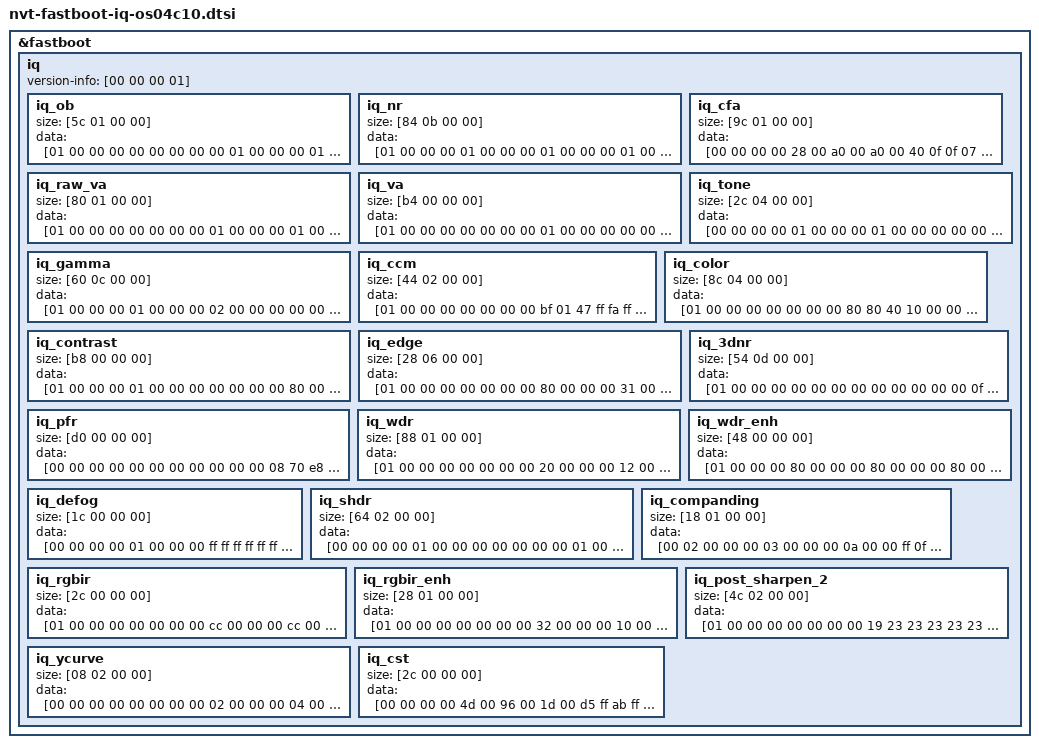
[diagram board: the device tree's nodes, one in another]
/*
 * Novatek Ltd. NVT98567 ISP part of dts
 */

&fastboot {
	iq {
		version-info = [00 00 00 01];
		iq_ob {
			size = [5c 01 00 00];
			data = [01 00 00 00 00 00 00 00 00 01 00 00 00 01 00 00 00 01 00 00 00 01 00 00 00 01 00 00 00 01 00 00 00 01 00 00 00 01 00 00 00 01 00 00 00 01 00 00 00 01 00 00 00 01 00 00 00 01 00 00 00 01 00 00 00 01 00 00 00 01 00 00 00 01 00 00 00 01 00 00 00 01 00 00 00 01 00 00 00 01 00 00 00 01 00 00 00 01 00 00 00 01 00 00 00 01 00 00 00 01 00 00 00 01 00 00 00 01 00 00 00 01 00 00 00 01 00 00 00 01 00 00 00 01 00 00 00 01 00 00 00 01 00 00 00 01 00 00 00 01 00 00 00 01 00 00 00 01 00 00 00 01 00 00 00 01 00 00 00 01 00 00 00 01 00 00 00 01 00 00 00 01 00 00 00 01 00 00 00 01 00 00 00 01 00 00 00 01 00 00 00 01 00 00 00 01 00 00 00 01 00 00 00 01 00 00 00 01 00 00 00 01 00 00 00 01 00 00 00 01 00 00 00 01 00 00 00 01 00 00 00 01 00 00 00 01 00 00 00 01 00 00 00 01 00 00 00 01 00 00 00 01 00 00 00 01 00 00 00 01 00 00 00 01 00 00 00 01 00 00 00 01 00 00 00 01 00 00 00 01 00 00 00 01 00 00 00 01 00 00 00 01 00 00 00 01 00 00 00 01 00 00 00 01 00 00 00 01 00 00 00 01 00 00 00 01 00 00 00 01 00 00 00 01 00 00 00 01 00 00 00 01 00 00 00 01 00 00];
		};
		iq_nr {
			size = [84 0b 00 00];
			data = [01 00 00 00 01 00 00 00 01 00 00 00 01 00 00 00 01 00 00 00 00 00 00 00 00 01 00 00 00 00 00 00 00 00 00 00 ff 0f ff 0f ff 0f ff 0f ff 0f ff 0f ff 0f ff 0f ff 0f ff 0f 00 01 80 00 00 00 00 00 00 00 00 00 00 00 00 00 00 00 00 00 00 00 00 00 00 00 00 00 00 00 00 00 00 00 00 00 00 00 00 00 00 00 00 00 00 00 00 00 00 00 00 00 00 00 00 00 00 00 00 00 00 00 00 00 00 00 00 00 00 00 00 00 00 00 00 00 00 00 00 00 00 00 00 00 00 00 00 00 00 00 00 00 00 00 00 00 00 00 00 00 00 00 00 00 80 00 00 00 64 00 00 00 00 00 00 00 00 00 00 00 00 02 08 50 01 02 1e 03 01 01 00 00 02 00 00 00 02 00 00 00 00 01 00 00 00 00 00 00 00 00 00 00 c6 02 0c 04 af 06 3d 09 41 0f c6 02 0c 04 af 06 3d 09 41 0f 00 00 80 00 00 00 00 00 00 00 00 00 01 00 01 00 01 00 02 00 00 00 01 00 02 00 03 00 04 00 04 00 04 00 05 00 05 00 06 00 06 00 06 00 06 00 07 00 07 00 07 00 08 00 00 00 00 00 03 00 03 00 03 00 06 00 00 00 02 00 02 00 03 00 04 00 04 00 04 00 05 00 05 00 06 00 06 00 06 00 06 00 07 00 07 00 07 00 08 00 00 00 80 00 80 00 00 00 64 00 00 00 00 00 00 00 00 00 00 00 00 02 08 50 01 02 1e 03 01 01 00 00 00 00 00 00 00 00 00 00 00 01 00 00 00 00 00 00 00 00 00 00 c6 02 0c 04 af 06 3d 09 41 0f c6 02 0c 04 af 06 3d 09 41 0f 00 00 80 00 00 00 00 00 00 00 01 00 02 00 03 00 04 00 05 00 00 00 01 00 02 00 03 00 04 00 04 00 04 00 05 00 05 00 06 00 06 00 06 00 06 00 07 00 07 00 07 00 08 00 00 00 06 00 06 00 09 00 0c 00 0f 00 00 00 02 00 02 00 03 00 04 00 04 00 04 00 05 00 05 00 06 00 06 00 06 00 06 00 07 00 07 00 07 00 08 00 00 00 80 00 80 00 00 00 64 00 00 00 00 00 00 00 00 00 00 00 00 02 08 50 01 02 1e 03 01 01 00 00 01 00 00 00 01 00 00 00 00 01 00 00 00 00 00 00 00 00 00 00 c6 02 0c 04 af 06 3d 09 41 0f c6 02 0c 04 af 06 3d 09 41 0f 00 00 80 00 00 00 00 00 00 00 02 00 03 00 04 00 05 00 07 00 00 00 03 00 04 00 05 00 06 00 07 00 07 00 08 00 09 00 09 00 0a 00 0a 00 0b 00 0b 00 0b 00 0c 00 0c 00 00 00 06 00 09 00 0c 00 0f 00 15 00 00 00 03 00 04 00 05 00 06 00 07 00 07 00 08 00 09 00 09 00 0a 00 0a 00 0b 00 0b 00 0b 00 0c 00 0c 00 00 00 60 00 80 00 00 00 64 00 00 00 00 00 00 00 00 00 00 00 00 02 08 50 01 02 1e 03 01 01 00 00 01 00 00 00 01 00 00 00 00 01 00 00 00 00 00 00 00 00 00 00 c6 02 0c 04 af 06 3d 09 41 0f c6 02 0c 04 af 06 3d 09 41 0f 09 00 80 00 00 00 00 00 00 00 02 00 03 00 04 00 05 00 07 00 00 00 04 00 05 00 06 00 08 00 08 00 09 00 0a 00 0b 00 0c 00 0c 00 0d 00 0d 00 0e 00 0e 00 0f 00 10 00 00 00 06 00 09 00 0c 00 0f 00 15 00 00 00 04 00 05 00 06 00 08 00 08 00 09 00 0a 00 0b 00 0c 00 0c 00 0d 00 0d 00 0e 00 0e 00 0f 00 10 00 00 00 20 00 80 00 00 00 64 00 00 00 00 00 00 00 00 00 00 00 00 02 08 50 01 02 1e 03 01 01 00 00 01 00 00 00 01 00 00 00 00 01 00 00 00 00 00 00 00 00 00 00 c6 02 0c 04 af 06 3d 09 41 0f c6 02 0c 04 af 06 3d 09 41 0f 09 00 80 00 00 00 00 00 00 00 03 00 04 00 05 00 06 00 09 00 00 00 05 00 07 00 09 00 0b 00 0c 00 0d 00 0e 00 0f 00 10 00 11 00 12 00 13 00 14 00 14 00 15 00 16 00 00 00 09 00 0c 00 0f 00 12 00 1b 00 00 00 05 00 07 00 09 00 0b 00 0c 00 0d 00 0e 00 0f 00 10 00 11 00 12 00 13 00 14 00 14 00 15 00 16 00 00 00 20 00 80 00 00 00 64 00 00 00 00 00 00 00 00 00 00 00 00 02 08 50 01 02 1e 03 01 01 00 00 02 00 00 00 02 00 00 00 00 01 00 00 00 00 00 00 00 00 00 00 c6 02 0c 04 af 06 3d 09 41 0f c6 02 0c 04 af 06 3d 09 41 0f 09 00 80 00 00 00 00 00 00 00 04 00 06 00 07 00 08 00 0c 00 00 00 07 00 0a 00 0c 00 0e 00 10 00 11 00 13 00 14 00 15 00 16 00 17 00 18 00 19 00 1a 00 1b 00 1c 00 00 00 0c 00 12 00 15 00 18 00 24 00 00 00 07 00 0a 00 0c 00 0e 00 10 00 11 00 13 00 14 00 15 00 16 00 17 00 18 00 19 00 1a 00 1b 00 1c 00 00 00 20 00 40 00 00 00 64 00 00 00 00 00 00 00 00 00 00 00 00 02 08 50 01 02 1e 03 01 01 00 00 02 00 00 00 02 00 00 00 00 01 00 00 00 00 00 00 00 00 00 00 c6 02 0c 04 af 06 3d 09 41 0f c6 02 0c 04 af 06 3d 09 41 0f 09 00 80 00 00 00 00 00 00 00 06 00 09 00 0b 00 0c 00 12 00 00 00 05 00 0a 00 14 00 17 00 19 00 1c 00 1e 00 20 00 22 00 24 00 26 00 28 00 29 00 2b 00 2c 00 2e 00 00 00 12 00 1b 00 21 00 24 00 36 00 00 00 05 00 0a 00 14 00 17 00 19 00 1c 00 1e 00 20 00 22 00 24 00 26 00 28 00 29 00 2b 00 2c 00 2e 00 00 00 20 00 40 00 00 00 64 00 00 00 00 00 00 00 00 00 00 00 00 02 08 50 01 02 1e 03 01 01 00 00 02 00 00 00 02 00 00 00 00 01 00 00 00 00 00 00 00 00 00 00 c6 02 0c 04 af 06 3d 09 41 0f c6 02 0c 04 af 06 3d 09 41 0f 09 00 80 00 00 00 00 00 00 00 06 00 08 00 0a 00 0c 00 11 00 00 00 10 00 17 00 1c 00 20 00 24 00 28 00 2b 00 2e 00 31 00 33 00 36 00 38 00 3b 00 3d 00 3f 00 41 00 00 00 12 00 18 00 1e 00 24 00 33 00 00 00 10 00 17 00 1c 00 20 00 24 00 28 00 2b 00 2e 00 31 00 33 00 36 00 38 00 3b 00 3d 00 3f 00 41 00 00 00 20 00 40 00 00 00 64 00 00 00 00 00 00 00 00 00 00 00 00 02 08 50 01 02 1e 03 01 01 00 00 02 00 00 00 02 00 00 00 00 01 00 00 00 00 00 00 00 00 00 00 c6 02 0c 04 af 06 3d 09 41 0f c6 02 0c 04 af 06 3d 09 41 0f 09 00 80 00 00 00 00 00 00 00 0b 00 10 00 13 00 16 00 20 00 00 00 11 00 18 00 1d 00 22 00 26 00 2a 00 2d 00 30 00 33 00 36 00 39 00 3b 00 3e 00 40 00 42 00 44 00 00 00 21 00 30 00 39 00 42 00 60 00 00 00 0f 00 1e 00 25 00 2b 00 30 00 34 00 39 00 3d 00 40 00 44 00 47 00 4a 00 4d 00 50 00 53 00 56 00 00 00 20 00 40 00 00 00 64 00 00 00 00 00 00 00 00 00 00 00 00 02 08 50 01 02 1e 03 01 01 00 00 02 00 00 00 03 00 00 00 00 01 00 00 00 00 00 00 00 00 00 00 c6 02 0c 04 af 06 3d 09 41 0f c6 02 0c 04 af 06 3d 09 41 0f 09 00 80 00 00 00 00 00 00 00 14 00 1c 00 23 00 28 00 39 00 00 00 11 00 18 00 1e 00 23 00 27 00 2b 00 2e 00 31 00 34 00 37 00 3a 00 3c 00 3f 00 41 00 44 00 46 00 00 00 33 00 4b 00 5d 00 69 00 96 00 00 00 18 00 2e 00 3f 00 49 00 52 00 5a 00 61 00 68 00 6e 00 74 00 7a 00 7f 00 84 00 89 00 8e 00 93 00 00 00 20 00 40 00 00 00 64 00 00 00 00 00 00 00 00 00 00 00 00 02 08 50 01 02 1e 03 01 01 00 00 02 00 00 00 03 00 00 00 00 01 00 00 00 00 00 00 00 00 00 00 c6 02 0c 04 af 06 3d 09 41 0f c6 02 0c 04 af 06 3d 09 41 0f 09 00 80 00 00 00 00 00 00 00 19 00 24 00 2c 00 33 00 49 00 00 00 14 00 1d 00 24 00 29 00 2e 00 32 00 37 00 3a 00 3e 00 41 00 44 00 48 00 4a 00 4d 00 50 00 53 00 00 00 63 00 93 00 ae 00 c9 00 1a 01 00 00 38 00 4f 00 60 00 70 00 7d 00 89 00 94 00 9e 00 a8 00 b1 00 b9 00 c1 00 c9 00 d1 00 d8 00 e0 00 00 00 00 00 20 00 00 00 64 00 00 00 00 00 00 00 00 00 00 00 00 02 08 50 01 02 1e 03 01 01 00 00 02 00 00 00 03 00 00 00 00 01 00 00 00 00 00 00 00 00 00 00 c6 02 0c 04 af 06 3d 09 41 0f c6 02 0c 04 af 06 3d 09 41 0f 09 00 80 00 00 00 00 00 00 00 10 00 16 00 1c 00 20 00 2d 00 00 00 12 00 18 00 20 00 25 00 2a 00 2e 00 31 00 35 00 38 00 3b 00 3e 00 41 00 43 00 46 00 48 00 4b 00 00 00 30 00 42 00 54 00 60 00 87 00 00 00 12 00 18 00 20 00 25 00 2a 00 2e 00 31 00 35 00 38 00 3b 00 3e 00 41 00 43 00 46 00 48 00 4b 00 00 00 20 00 20 00 00 00 64 00 00 00 00 00 00 00 00 00 00 00 00 02 08 50 01 02 1e 03 01 01 00 00 02 00 00 00 03 00 00 00 00 01 00 00 00 00 00 00 00 00 00 00 14 02 03 03 f8 04 34 07 e3 0b 14 02 03 03 f8 04 34 07 e3 0b 09 00 80 00 00 00 00 00 00 00 11 00 18 00 1e 00 23 00 31 00 00 00 30 00 43 00 53 00 60 00 6b 00 75 00 7e 00 87 00 90 00 97 00 9f 00 a6 00 ad 00 b3 00 b9 00 c0 00 00 00 33 00 48 00 5a 00 69 00 93 00 00 00 30 00 43 00 53 00 60 00 6b 00 75 00 7e 00 87 00 90 00 97 00 9f 00 a6 00 ad 00 b3 00 b9 00 c0 00 00 00 20 00 20 00 00 00 64 00 00 00 00 00 00 00 00 00 00 00 00 02 08 50 01 02 1e 03 01 01 00 00 02 00 00 00 02 00 00 00 00 01 00 00 00 00 00 00 00 00 00 00 9a 01 53 02 d6 03 90 05 2e 09 9a 01 53 02 d6 03 90 05 2e 09 09 00 80 00 00 00 00 00 00 00 11 00 18 00 1e 00 23 00 31 00 00 00 30 00 43 00 53 00 60 00 6b 00 75 00 7e 00 87 00 90 00 97 00 9f 00 a6 00 ad 00 b3 00 b9 00 c0 00 00 00 33 00 54 00 5a 00 69 00 93 00 00 00 30 00 43 00 53 00 60 00 6b 00 75 00 7e 00 87 00 90 00 97 00 9f 00 a6 00 ad 00 b3 00 b9 00 c0 00 00 00 20 00 20 00 00 00 64 00 00 00 00 00 00 00 00 00 00 00 00 02 08 50 01 02 1e 03 01 01 00 00 02 00 00 00 02 00 00 00 00 01 00 00 00 00 00 00 00 00 00 00 9a 01 53 02 d6 03 90 05 2e 09 9a 01 53 02 d6 03 90 05 2e 09 09 00 80 00 00 00 00 00 00 00 11 00 18 00 1e 00 23 00 31 00 00 00 30 00 43 00 53 00 60 00 6b 00 75 00 7e 00 87 00 90 00 97 00 9f 00 a6 00 ad 00 b3 00 b9 00 c0 00 00 00 33 00 54 00 5a 00 69 00 93 00 00 00 30 00 43 00 53 00 60 00 6b 00 75 00 7e 00 87 00 90 00 97 00 9f 00 a6 00 ad 00 b3 00 b9 00 c0 00 00 00 20 00 20 00 00 00 64 00 00 00 00 00 00 00 00 00 00 00 00 02 08 50 01 02 1e 03 01 01 00 00 02 00 00 00 02 00 00 00 00 01 00 00 00 00 00 00 00 00 00 00 9a 01 53 02 d6 03 90 05 2e 09 9a 01 53 02 d6 03 90 05 2e 09 09 00 80 00 00 00 00 00 00 00 11 00 18 00 1e 00 23 00 31 00 00 00 30 00 43 00 53 00 60 00 6b 00 75 00 7e 00 87 00 90 00 97 00 9f 00 a6 00 ad 00 b3 00 b9 00 c0 00 00 00 33 00 54 00 5a 00 69 00 93 00 00 00 30 00 43 00 53 00 60 00 6b 00 75 00 7e 00 87 00 90 00 97 00 9f 00 a6 00 ad 00 b3 00 b9 00 c0 00 00 00 20 00 20 00 00 00 64 00 00 00 00 00 00 00 00 00 00 00 00 02 08 50 01 02 1e 03 01 01 00 00 02 00 00 00 02 00 00 00];
		};
		iq_cfa {
			size = [9c 01 00 00];
			data = [00 00 00 00 28 00 a0 00 a0 00 40 0f 0f 07 04 03 02 02 01 01 01 01 00 00 00 00 00 00 28 00 a0 00 a0 00 40 0f 0f 07 04 03 02 02 01 01 01 01 00 00 00 00 00 00 28 00 a0 00 a0 00 40 0f 0f 07 04 03 02 02 01 01 01 01 00 00 00 00 00 00 28 00 a0 00 a0 00 40 0f 0f 07 04 03 02 02 01 01 01 01 00 00 00 00 00 00 28 00 a0 00 a0 00 40 0f 0f 07 04 03 02 02 01 01 01 01 00 00 00 00 00 00 28 00 a0 00 a0 00 40 0f 0f 07 04 03 02 02 01 01 01 01 00 00 00 00 00 00 28 00 a0 00 a0 00 40 0f 0f 07 04 03 02 02 01 01 01 01 00 00 00 00 00 00 28 00 a0 00 a0 00 40 0f 0f 07 04 03 02 02 01 01 01 01 00 00 00 00 00 00 28 00 a0 00 a0 00 40 0f 0f 07 04 03 02 02 01 01 01 01 00 00 00 00 00 00 28 00 a0 00 a0 00 40 0f 0f 07 04 03 02 02 01 01 01 01 00 00 00 00 00 00 28 00 a0 00 a0 00 40 0f 0f 07 04 03 02 02 01 01 01 01 00 00 00 00 00 00 28 00 a0 00 a0 00 40 0f 0f 07 04 03 02 02 01 01 01 01 00 00 00 00 00 00 28 00 a0 00 a0 00 40 0f 0f 07 04 03 02 02 01 01 01 01 00 00 00 00 00 00 28 00 a0 00 a0 00 40 0f 0f 07 04 03 02 02 01 01 01 01 00 00 00 00 00 00 28 00 a0 00 a0 00 40 0f 0f 07 04 03 02 02 01 01 01 01 00 00 00 00 00 00 28 00 a0 00 a0 00 40 0f 0f 07 04 03 02 02 01 01 01 01 00 00 00 00 00 00 28 00 a0 00 a0 00 40 0f 0f 07 04 03 02 02 01 01 01 01 00 00 00 00 00 00];
		};
		iq_raw_va {
			size = [80 01 00 00];
			data = [01 00 00 00 00 00 00 00 01 00 00 00 01 00 00 00 00 00 00 00 ff ff 00 00 03 00 00 00 01 00 00 00 00 00 00 00 02 00 00 00 ff ff 00 00 03 0a 96 ff ff 02 06 10 00 00 00 00 96 00 00 00 2c 00 a9 fe ca 00 06 00 00 00 2c 00 45 fe df 00 08 00 00 00 29 00 ae 00 00 00 08 00 00 00 00 00 00 00 2c 00 a9 fe ca 00 06 00 00 00 2c 00 45 fe df 00 08 00 00 00 29 00 ae 00 00 00 08 00 00 00 00 00 00 00 00 00 00 00 00 00 00 00 00 00 00 00 00 00 00 00 00 00 00 00 00 00 00 00 00 00 00 00 00 00 00 00 00 00 00 00 00 00 00 00 00 00 00 00 00 00 00 00 00 00 00 00 00 00 00 00 00 00 00 00 00 00 00 00 00 00 00 00 00 00 00 00 00 00 00 00 00 00 00 00 01 00 00 00 00 00 00 00 01 00 00 00 00 00 00 00 01 00 00 00 00 00 00 00 01 00 00 00 00 00 00 00 01 00 00 00 00 00 00 00 01 00 00 00 00 00 00 00 02 00 00 00 00 00 00 00 02 00 00 00 00 00 00 00 02 00 00 00 00 00 00 00 02 00 00 00 00 00 00 00 02 00 00 00 00 00 00 00 02 00 00 00 00 00 00 00 03 00 00 00 00 00 00 00 03 00 00 00 00 00 00 00 03 00 00 00 00 00 00 00 03 00 00 00 00 00 00 00 03 00 00 00 00 00 00 00 03 00 00 00 00 00 00 00 03 00 00 00 00 00 00 00 03 00 00 00 00 00 00 00 03 00 00 00 00 00 00 00 03 00 00 00 00 00 00 00];
		};
		iq_va {
			size = [b4 00 00 00];
			data = [01 00 00 00 00 00 00 00 01 00 00 00 00 00 ff 00 02 00 00 00 00 00 00 00 02 00 ff 00 03 0a 96 ff ff 02 06 10 00 00 00 00 96 00 00 00 00 00 00 00 00 00 00 00 00 00 00 00 00 00 00 00 00 00 00 00 00 00 00 00 00 00 00 00 00 00 00 00 00 00 00 00 00 00 00 00 00 00 00 00 00 00 00 00 00 00 00 00 00 00 00 00 00 00 00 00 00 00 00 00 00 00 00 00 00 00 00 00 00 00 00 00 00 00 00 00 00 00 00 00 00 00 00 00 00 00 00 00 00 00 00 00 00 00 00 00 00 00 00 00 00 00 00 00 00 00 00 00 00 00 00 00 00 00 00 00 00 00 00 00 00 00 00 00 00 00 00 00 00 00 00 00];
		};
		iq_tone {
			size = [2c 04 00 00];
			data = [00 00 00 00 01 00 00 00 01 00 00 00 00 00 00 00 00 00 00 00 00 00 00 00 8e 00 1c 01 aa 01 38 02 a9 02 1b 03 8c 03 fd 03 59 04 b5 04 11 05 6d 05 ba 05 06 06 53 06 9f 06 e0 06 20 07 61 07 a1 07 d8 07 0f 08 46 08 7d 08 ad 08 dd 08 0c 09 3c 09 66 09 90 09 b9 09 e3 09 08 0a 2d 0a 51 0a 76 0a 97 0a b7 0a d8 0a f8 0a 15 0b 33 0b 50 0b 6d 0b 88 0b a2 0b bd 0b d7 0b ef 0b 07 0c 1e 0c 36 0c 4c 0c 62 0c 77 0c 8d 0c a1 0c b5 0c c9 0c dd 0c ef 0c 02 0d 14 0d 26 0d 26 0d 6a 0d a8 0d e3 0d 1a 0e 4e 0e 7e 0e ac 0e d8 0e 02 0f 2a 0f 50 0f 75 0f 99 0f bc 0f de 0f ff 0f 00 00 00 00 00 00 00 00 e0 00 9e 01 43 02 d5 02 58 03 cf 03 3b 04 9e 04 03 05 5d 05 ab 05 ed 05 12 06 37 06 59 06 7a 06 93 06 ac 06 c5 06 de 06 f7 06 0f 07 27 07 40 07 58 07 6f 07 87 07 9f 07 b6 07 cd 07 e4 07 fc 07 13 08 2a 08 41 08 58 08 6e 08 85 08 9c 08 b2 08 c9 08 df 08 f5 08 0c 09 22 09 38 09 4e 09 64 09 7a 09 90 09 a6 09 bc 09 d2 09 e8 09 fe 09 13 0a 29 0a 3f 0a 54 0a 6a 0a 80 0a 95 0a ab 0a c0 0a c0 0a 16 0b 6c 0b c1 0b 16 0c 6a 0c bf 0c 13 0d 67 0d ba 0d 0e 0e 61 0e b4 0e 07 0f 5a 0f ad 0f ff 0f 19 00 00 00 00 00 57 01 59 02 27 03 d4 03 68 04 e9 04 5c 05 c4 05 2a 06 84 06 d1 06 12 07 35 07 57 07 77 07 96 07 ac 07 c2 07 d8 07 ef 07 04 08 1a 08 30 08 46 08 5b 08 70 08 85 08 9b 08 af 08 c4 08 d8 08 ed 08 01 09 16 09 2a 09 3e 09 52 09 66 09 7a 09 8e 09 a2 09 b6 09 c9 09 dd 09 f1 09 04 0a 18 0a 2b 0a 3f 0a 52 0a 66 0a 79 0a 8c 0a a0 0a b3 0a c6 0a d9 0a ec 0a ff 0a 13 0b 26 0b 39 0b 4c 0b 5f 0b 5f 0b aa 0b f6 0b 41 0c 8c 0c d6 0c 21 0d 6b 0d b5 0d ff 0d 48 0e 92 0e db 0e 24 0f 6e 0f b7 0f ff 0f 32 00 00 00 00 00 1e 02 69 03 58 04 14 05 ad 05 30 06 a2 06 06 07 67 07 bc 07 04 08 41 08 60 08 7e 08 9b 08 b6 08 c9 08 dd 08 f0 08 04 09 17 09 2a 09 3d 09 50 09 62 09 75 09 87 09 9a 09 ac 09 bd 09 cf 09 e1 09 f3 09 04 0a 16 0a 27 0a 39 0a 4a 0a 5b 0a 6c 0a 7e 0a 8f 0a a0 0a b1 0a c2 0a d3 0a e4 0a f5 0a 05 0b 16 0b 27 0b 38 0b 48 0b 59 0b 6a 0b 7a 0b 8b 0b 9c 0b ac 0b bd 0b cd 0b de 0b ee 0b fe 0b fe 0b 40 0c 81 0c c2 0c 03 0d 43 0d 84 0d c4 0d 04 0e 44 0e 83 0e c3 0e 03 0f 42 0f 81 0f c0 0f ff 0f 4b 00 00 00 00 00 69 02 c7 03 bb 04 77 05 11 06 92 06 01 07 64 07 c2 07 15 08 5b 08 96 08 b4 08 d1 08 ed 08 07 09 19 09 2c 09 3f 09 51 09 63 09 76 09 88 09 9a 09 ab 09 bd 09 ce 09 e0 09 f1 09 02 0a 13 0a 25 0a 36 0a 46 0a 57 0a 68 0a 79 0a 89 0a 9a 0a aa 0a bb 0a cb 0a db 0a ec 0a fc 0a 0c 0b 1c 0b 2c 0b 3d 0b 4d 0b 5d 0b 6d 0b 7d 0b 8d 0b 9d 0b ac 0b bc 0b cc 0b dc 0b ec 0b fc 0b 0b 0c 1b 0c 2b 0c 2b 0c 69 0c a8 0c e6 0c 24 0d 62 0d 9f 0d dd 0d 1a 0e 57 0e 94 0e d1 0e 0d 0f 4a 0f 87 0f c3 0f ff 0f 64 00 00 00 00 00 22 03 9b 04 93 05 4d 06 e1 06 5d 07 c7 07 23 08 7b 08 c8 08 0a 09 41 09 5c 09 77 09 90 09 a8 09 b9 09 ca 09 dc 09 ed 09 fd 09 0e 0a 1e 0a 2f 0a 3f 0a 4e 0a 5e 0a 6e 0a 7d 0a 8d 0a 9d 0a ad 0a bc 0a cb 0a db 0a ea 0a f9 0a 08 0b 17 0b 26 0b 35 0b 44 0b 53 0b 62 0b 70 0b 7f 0b 8e 0b 9c 0b ab 0b ba 0b c8 0b d7 0b e5 0b f4 0b 02 0c 11 0c 1f 0c 2e 0c 3c 0c 4a 0c 59 0c 67 0c 75 0c 84 0c 84 0c bd 0c f5 0c 2e 0d 66 0d 9e 0d d6 0d 0e 0e 46 0e 7d 0e b5 0e ec 0e 23 0f 5b 0f 92 0f c9 0f ff 0f 06 00 00 00 32 00 00 00 04 00 00 00 32 00 00 00 02 00 00 00 32 00 00 00 01 00 00 00 32 00 00 00 00 00 00 00 32 00 00 00];
		};
		iq_gamma {
			size = [60 0c 00 00];
			data = [01 00 00 00 01 00 00 00 02 00 00 00 00 00 00 00 25 00 00 00 49 00 00 00 6b 00 00 00 8b 00 00 00 a9 00 00 00 c6 00 00 00 e1 00 00 00 f1 00 00 00 01 01 00 00 11 01 00 00 21 01 00 00 30 01 00 00 3e 01 00 00 4d 01 00 00 5b 01 00 00 68 01 00 00 75 01 00 00 82 01 00 00 8f 01 00 00 9b 01 00 00 a6 01 00 00 b1 01 00 00 bc 01 00 00 c7 01 00 00 d1 01 00 00 db 01 00 00 e4 01 00 00 ed 01 00 00 f6 01 00 00 fe 01 00 00 06 02 00 00 0d 02 00 00 14 02 00 00 1b 02 00 00 22 02 00 00 29 02 00 00 30 02 00 00 36 02 00 00 3d 02 00 00 44 02 00 00 4b 02 00 00 52 02 00 00 59 02 00 00 5f 02 00 00 66 02 00 00 6d 02 00 00 73 02 00 00 7a 02 00 00 80 02 00 00 87 02 00 00 8d 02 00 00 93 02 00 00 9a 02 00 00 a0 02 00 00 a6 02 00 00 ac 02 00 00 b3 02 00 00 b9 02 00 00 bf 02 00 00 c5 02 00 00 cb 02 00 00 d1 02 00 00 d7 02 00 00 dd 02 00 00 e3 02 00 00 e8 02 00 00 ee 02 00 00 f4 02 00 00 fa 02 00 00 ff 02 00 00 04 03 00 00 09 03 00 00 0e 03 00 00 13 03 00 00 18 03 00 00 1d 03 00 00 21 03 00 00 26 03 00 00 2b 03 00 00 30 03 00 00 35 03 00 00 3a 03 00 00 3e 03 00 00 43 03 00 00 48 03 00 00 4d 03 00 00 51 03 00 00 56 03 00 00 5b 03 00 00 5f 03 00 00 64 03 00 00 68 03 00 00 6d 03 00 00 72 03 00 00 76 03 00 00 7b 03 00 00 7f 03 00 00 84 03 00 00 88 03 00 00 8c 03 00 00 91 03 00 00 95 03 00 00 99 03 00 00 9e 03 00 00 a2 03 00 00 a6 03 00 00 ab 03 00 00 af 03 00 00 b3 03 00 00 b7 03 00 00 bb 03 00 00 bf 03 00 00 c4 03 00 00 c8 03 00 00 cc 03 00 00 d0 03 00 00 d4 03 00 00 d8 03 00 00 dc 03 00 00 e0 03 00 00 e4 03 00 00 e8 03 00 00 eb 03 00 00 ef 03 00 00 f3 03 00 00 f7 03 00 00 fb 03 00 00 ff 03 00 00 00 00 00 00 00 00 00 00 08 00 00 00 10 00 00 00 18 00 00 00 20 00 00 00 28 00 00 00 30 00 00 00 38 00 00 00 40 00 00 00 48 00 00 00 50 00 00 00 58 00 00 00 60 00 00 00 68 00 00 00 70 00 00 00 78 00 00 00 80 00 00 00 88 00 00 00 90 00 00 00 98 00 00 00 a0 00 00 00 a8 00 00 00 b0 00 00 00 b8 00 00 00 c0 00 00 00 c8 00 00 00 d0 00 00 00 d8 00 00 00 e0 00 00 00 e8 00 00 00 f0 00 00 00 f8 00 00 00 00 01 00 00 08 01 00 00 10 01 00 00 18 01 00 00 20 01 00 00 28 01 00 00 30 01 00 00 38 01 00 00 40 01 00 00 48 01 00 00 50 01 00 00 58 01 00 00 60 01 00 00 68 01 00 00 70 01 00 00 78 01 00 00 80 01 00 00 88 01 00 00 90 01 00 00 98 01 00 00 a0 01 00 00 a8 01 00 00 b0 01 00 00 b8 01 00 00 c0 01 00 00 c8 01 00 00 d0 01 00 00 d8 01 00 00 e0 01 00 00 e8 01 00 00 f0 01 00 00 f7 01 00 00 ff 01 00 00 07 02 00 00 0f 02 00 00 17 02 00 00 1f 02 00 00 27 02 00 00 2f 02 00 00 37 02 00 00 3f 02 00 00 47 02 00 00 4f 02 00 00 57 02 00 00 5f 02 00 00 67 02 00 00 6f 02 00 00 77 02 00 00 7f 02 00 00 87 02 00 00 8f 02 00 00 97 02 00 00 9f 02 00 00 a7 02 00 00 af 02 00 00 b7 02 00 00 bf 02 00 00 c7 02 00 00 cf 02 00 00 d7 02 00 00 df 02 00 00 e7 02 00 00 ef 02 00 00 f7 02 00 00 ff 02 00 00 07 03 00 00 0f 03 00 00 17 03 00 00 1f 03 00 00 27 03 00 00 2f 03 00 00 37 03 00 00 3f 03 00 00 47 03 00 00 4f 03 00 00 57 03 00 00 5f 03 00 00 67 03 00 00 6f 03 00 00 77 03 00 00 7f 03 00 00 87 03 00 00 8f 03 00 00 97 03 00 00 9f 03 00 00 a7 03 00 00 af 03 00 00 b7 03 00 00 bf 03 00 00 c7 03 00 00 cf 03 00 00 d7 03 00 00 df 03 00 00 e7 03 00 00 ef 03 00 00 f7 03 00 00 ff 03 00 00 19 00 00 00 00 00 00 00 22 00 00 00 36 00 00 00 47 00 00 00 57 00 00 00 65 00 00 00 73 00 00 00 80 00 00 00 8c 00 00 00 98 00 00 00 a4 00 00 00 b0 00 00 00 bb 00 00 00 c6 00 00 00 d1 00 00 00 dc 00 00 00 e7 00 00 00 f1 00 00 00 fc 00 00 00 06 01 00 00 10 01 00 00 1b 01 00 00 25 01 00 00 2f 01 00 00 39 01 00 00 43 01 00 00 4d 01 00 00 57 01 00 00 60 01 00 00 6a 01 00 00 74 01 00 00 7d 01 00 00 87 01 00 00 90 01 00 00 9a 01 00 00 a3 01 00 00 ac 01 00 00 b6 01 00 00 bf 01 00 00 c8 01 00 00 d1 01 00 00 da 01 00 00 e3 01 00 00 ec 01 00 00 f5 01 00 00 fd 01 00 00 06 02 00 00 0f 02 00 00 17 02 00 00 20 02 00 00 28 02 00 00 30 02 00 00 39 02 00 00 41 02 00 00 49 02 00 00 51 02 00 00 59 02 00 00 61 02 00 00 69 02 00 00 71 02 00 00 78 02 00 00 80 02 00 00 88 02 00 00 8f 02 00 00 97 02 00 00 9e 02 00 00 a5 02 00 00 ad 02 00 00 b4 02 00 00 bb 02 00 00 c2 02 00 00 c9 02 00 00 d0 02 00 00 d7 02 00 00 dd 02 00 00 e4 02 00 00 eb 02 00 00 f1 02 00 00 f8 02 00 00 fe 02 00 00 05 03 00 00 0b 03 00 00 11 03 00 00 17 03 00 00 1e 03 00 00 24 03 00 00 2a 03 00 00 30 03 00 00 36 03 00 00 3b 03 00 00 41 03 00 00 47 03 00 00 4d 03 00 00 52 03 00 00 58 03 00 00 5d 03 00 00 63 03 00 00 68 03 00 00 6e 03 00 00 73 03 00 00 78 03 00 00 7d 03 00 00 83 03 00 00 88 03 00 00 8d 03 00 00 92 03 00 00 97 03 00 00 9c 03 00 00 a1 03 00 00 a6 03 00 00 ab 03 00 00 b0 03 00 00 b5 03 00 00 b9 03 00 00 be 03 00 00 c3 03 00 00 c8 03 00 00 cc 03 00 00 d1 03 00 00 d6 03 00 00 da 03 00 00 df 03 00 00 e4 03 00 00 e8 03 00 00 ed 03 00 00 f1 03 00 00 f6 03 00 00 fa 03 00 00 ff 03 00 00 32 00 00 00 00 00 00 00 25 00 00 00 49 00 00 00 6b 00 00 00 8b 00 00 00 a9 00 00 00 c6 00 00 00 e1 00 00 00 f1 00 00 00 01 01 00 00 11 01 00 00 21 01 00 00 30 01 00 00 3e 01 00 00 4d 01 00 00 5b 01 00 00 68 01 00 00 75 01 00 00 82 01 00 00 8f 01 00 00 9b 01 00 00 a6 01 00 00 b1 01 00 00 bc 01 00 00 c7 01 00 00 d1 01 00 00 db 01 00 00 e4 01 00 00 ed 01 00 00 f6 01 00 00 fe 01 00 00 06 02 00 00 0d 02 00 00 14 02 00 00 1b 02 00 00 22 02 00 00 29 02 00 00 30 02 00 00 36 02 00 00 3d 02 00 00 44 02 00 00 4b 02 00 00 52 02 00 00 59 02 00 00 5f 02 00 00 66 02 00 00 6d 02 00 00 73 02 00 00 7a 02 00 00 80 02 00 00 87 02 00 00 8d 02 00 00 93 02 00 00 9a 02 00 00 a0 02 00 00 a6 02 00 00 ac 02 00 00 b3 02 00 00 b9 02 00 00 bf 02 00 00 c5 02 00 00 cb 02 00 00 d1 02 00 00 d7 02 00 00 dd 02 00 00 e3 02 00 00 e8 02 00 00 ee 02 00 00 f4 02 00 00 fa 02 00 00 ff 02 00 00 04 03 00 00 09 03 00 00 0e 03 00 00 13 03 00 00 18 03 00 00 1d 03 00 00 21 03 00 00 26 03 00 00 2b 03 00 00 30 03 00 00 35 03 00 00 3a 03 00 00 3e 03 00 00 43 03 00 00 48 03 00 00 4d 03 00 00 51 03 00 00 56 03 00 00 5b 03 00 00 5f 03 00 00 64 03 00 00 68 03 00 00 6d 03 00 00 72 03 00 00 76 03 00 00 7b 03 00 00 7f 03 00 00 84 03 00 00 88 03 00 00 8c 03 00 00 91 03 00 00 95 03 00 00 99 03 00 00 9e 03 00 00 a2 03 00 00 a6 03 00 00 ab 03 00 00 af 03 00 00 b3 03 00 00 b7 03 00 00 bb 03 00 00 bf 03 00 00 c4 03 00 00 c8 03 00 00 cc 03 00 00 d0 03 00 00 d4 03 00 00 d8 03 00 00 dc 03 00 00 e0 03 00 00 e4 03 00 00 e8 03 00 00 eb 03 00 00 ef 03 00 00 f3 03 00 00 f7 03 00 00 fb 03 00 00 ff 03 00 00 4b 00 00 00 00 00 00 00 94 00 00 00 c3 00 00 00 e6 00 00 00 03 01 00 00 1c 01 00 00 33 01 00 00 48 01 00 00 5b 01 00 00 6d 01 00 00 7e 01 00 00 8e 01 00 00 9d 01 00 00 ac 01 00 00 ba 01 00 00 c7 01 00 00 d4 01 00 00 e0 01 00 00 ec 01 00 00 f8 01 00 00 03 02 00 00 0e 02 00 00 18 02 00 00 22 02 00 00 2c 02 00 00 36 02 00 00 3f 02 00 00 48 02 00 00 51 02 00 00 5a 02 00 00 62 02 00 00 6b 02 00 00 73 02 00 00 7b 02 00 00 82 02 00 00 8a 02 00 00 91 02 00 00 98 02 00 00 a0 02 00 00 a6 02 00 00 ad 02 00 00 b4 02 00 00 ba 02 00 00 c1 02 00 00 c7 02 00 00 cd 02 00 00 d3 02 00 00 d9 02 00 00 df 02 00 00 e5 02 00 00 ea 02 00 00 f0 02 00 00 f5 02 00 00 fb 02 00 00 00 03 00 00 05 03 00 00 0a 03 00 00 0f 03 00 00 14 03 00 00 19 03 00 00 1e 03 00 00 22 03 00 00 27 03 00 00 2c 03 00 00 30 03 00 00 35 03 00 00 39 03 00 00 3d 03 00 00 42 03 00 00 46 03 00 00 4a 03 00 00 4e 03 00 00 52 03 00 00 56 03 00 00 5a 03 00 00 5e 03 00 00 62 03 00 00 66 03 00 00 69 03 00 00 6d 03 00 00 71 03 00 00 74 03 00 00 78 03 00 00 7b 03 00 00 7f 03 00 00 82 03 00 00 86 03 00 00 89 03 00 00 8d 03 00 00 90 03 00 00 93 03 00 00 97 03 00 00 9a 03 00 00 9d 03 00 00 a0 03 00 00 a3 03 00 00 a6 03 00 00 aa 03 00 00 ad 03 00 00 b0 03 00 00 b3 03 00 00 b6 03 00 00 b9 03 00 00 bc 03 00 00 bf 03 00 00 c1 03 00 00 c4 03 00 00 c7 03 00 00 ca 03 00 00 cd 03 00 00 d0 03 00 00 d2 03 00 00 d5 03 00 00 d8 03 00 00 db 03 00 00 dd 03 00 00 e0 03 00 00 e3 03 00 00 e5 03 00 00 e8 03 00 00 eb 03 00 00 ed 03 00 00 f0 03 00 00 f2 03 00 00 f5 03 00 00 f7 03 00 00 fa 03 00 00 fc 03 00 00 ff 03 00 00 64 00 00 00 00 00 00 00 d2 00 00 00 09 01 00 00 31 01 00 00 52 01 00 00 6d 01 00 00 85 01 00 00 9b 01 00 00 af 01 00 00 c1 01 00 00 d2 01 00 00 e2 01 00 00 f1 01 00 00 00 02 00 00 0d 02 00 00 1a 02 00 00 26 02 00 00 31 02 00 00 3d 02 00 00 47 02 00 00 52 02 00 00 5b 02 00 00 65 02 00 00 6e 02 00 00 77 02 00 00 80 02 00 00 88 02 00 00 90 02 00 00 98 02 00 
00 9f 02 00 00 a7 02 00 00 ae 02 00 00 b5 02 00 00 bc 02 00 00 c2 02 00 00 c9 02 00 00 cf 02 00 00 d5 02 00 00 db 02 00 00 e1 02 00 00 e7 02 00 00 ed 02 00 00 f2 02 00 00 f8 02 00 00 fd 02 00 00 02 03 00 00 07 03 00 00 0c 03 00 00 11 03 00 00 16 03 00 00 1b 03 00 00 1f 03 00 00 24 03 00 00 28 03 00 00 2c 03 00 00 31 03 00 00 35 03 00 00 39 03 00 00 3d 03 00 00 41 03 00 00 45 03 00 00 49 03 00 00 4d 03 00 00 51 03 00 00 54 03 00 00 58 03 00 00 5c 03 00 00 5f 03 00 00 63 03 00 00 66 03 00 00 6a 03 00 00 6d 03 00 00 70 03 00 00 74 03 00 00 77 03 00 00 7a 03 00 00 7d 03 00 00 81 03 00 00 84 03 00 00 87 03 00 00 8a 03 00 00 8d 03 00 00 90 03 00 00 93 03 00 00 96 03 00 00 98 03 00 00 9b 03 00 00 9e 03 00 00 a1 03 00 00 a4 03 00 00 a6 03 00 00 a9 03 00 00 ac 03 00 00 ae 03 00 00 b1 03 00 00 b4 03 00 00 b6 03 00 00 b9 03 00 00 bb 03 00 00 be 03 00 00 c0 03 00 00 c3 03 00 00 c5 03 00 00 c8 03 00 00 ca 03 00 00 cc 03 00 00 cf 03 00 00 d1 03 00 00 d3 03 00 00 d6 03 00 00 d8 03 00 00 da 03 00 00 dd 03 00 00 df 03 00 00 e1 03 00 00 e3 03 00 00 e6 03 00 00 e8 03 00 00 ea 03 00 00 ec 03 00 00 ee 03 00 00 f0 03 00 00 f2 03 00 00 f5 03 00 00 f7 03 00 00 f9 03 00 00 fb 03 00 00 fd 03 00 00 ff 03 00 00 06 00 00 00 32 00 00 00 04 00 00 00 32 00 00 00 02 00 00 00 32 00 00 00 01 00 00 00 32 00 00 00 00 00 00 00 32 00 00 00];
		};
		iq_ccm {
			size = [44 02 00 00];
			data = [01 00 00 00 00 00 00 00 bf 01 47 ff fa ff 9c ff 96 01 ce ff 0d 00 e3 fe 0f 02 80 80 80 80 80 80 80 80 80 80 80 80 80 80 80 80 80 80 80 80 80 80 80 80 00 00 00 00 00 00 00 00 00 00 00 00 00 00 00 00 00 00 00 00 00 00 00 00 00 00 00 00 00 00 00 00 00 00 00 00 00 00 00 00 00 00 00 00 00 00 00 00 00 00 70 17 00 00 8b 01 ca ff ab ff ba ff c1 01 85 ff 0e 00 56 ff 9c 01 80 80 80 80 80 80 82 80 7e 80 80 80 80 80 80 80 80 80 80 80 80 80 80 80 00 00 00 00 00 00 22 1c 19 00 00 00 00 00 00 00 00 00 00 00 00 00 00 00 00 00 00 00 00 00 00 00 00 00 00 00 00 00 00 00 00 00 00 00 00 00 00 00 00 00 94 11 00 00 bb 01 7a ff cc ff 87 ff a1 01 d8 ff 04 00 64 ff 97 01 80 80 80 80 80 80 82 80 80 80 80 80 80 80 80 80 80 80 80 80 80 80 80 80 00 00 00 00 00 00 21 20 22 00 00 00 00 00 00 00 00 00 00 00 00 00 00 00 00 00 00 00 00 00 00 00 00 00 00 00 00 00 00 00 00 00 00 00 00 00 00 00 00 00 b8 0b 00 00 e2 00 70 00 ae ff 86 ff aa 01 d0 ff ed ff 40 ff d4 01 80 80 80 80 80 80 82 80 7e 80 80 80 80 80 80 80 80 80 80 80 80 80 80 80 00 00 00 00 00 00 20 18 17 00 00 00 00 00 00 00 00 00 00 00 00 00 00 00 00 00 00 00 00 00 00 00 00 00 00 00 00 00 00 00 00 00 00 00 00 00 00 00 00 00 74 0e 00 00 a0 01 93 ff cd ff 9b ff 82 01 e3 ff 64 00 81 fe 1c 02 80 80 80 80 80 80 80 80 80 80 80 80 80 80 80 80 80 80 80 80 80 80 80 80 00 00 00 00 00 00 00 00 00 00 00 00 00 00 00 00 00 00 00 00 00 00 00 00 00 00 00 00 00 00 00 00 00 00 00 00 00 00 00 00 00 00 00 00 00 00 00 00 00 00 f0 0a 00 00 a0 01 93 ff cd ff 9b ff 82 01 e3 ff 64 00 81 fe 1c 02 80 80 80 80 80 80 80 80 80 80 80 80 80 80 80 80 80 80 80 80 80 80 80 80 00 00 00 00 00 00 00 00 00 00 00 00 00 00 00 00 00 00 00 00 00 00 00 00 00 00 00 00 00 00 00 00 00 00 00 00 00 00 00 00 00 00 00 00 00 00 00 00 00 00];
		};
		iq_color {
			size = [8c 04 00 00];
			data = [01 00 00 00 00 00 00 00 80 80 40 10 00 00 00 00 00 00 00 00 00 00 00 00 00 14 0f 0a 05 00 00 00 00 00 00 00 00 00 05 0a 0f 00 80 00 80 00 80 00 80 00 80 00 80 00 80 00 80 00 80 00 80 00 80 00 80 00 80 00 80 00 80 00 80 00 80 00 80 80 40 10 00 00 00 00 00 00 00 00 00 00 00 00 00 14 0f 0a 05 00 00 00 00 00 00 00 00 00 05 0a 0f 00 80 00 80 00 80 00 80 00 80 00 80 00 80 00 80 00 80 00 80 00 80 00 80 00 80 00 80 00 80 00 80 00 80 00 80 80 40 10 00 00 00 00 00 00 00 00 00 00 00 00 00 14 0f 0a 05 00 00 00 00 00 00 00 00 00 05 0a 0f 00 80 00 80 00 80 00 80 00 80 00 80 00 80 00 80 00 80 00 80 00 80 00 80 00 80 00 80 00 80 00 80 00 80 00 80 80 40 10 00 00 00 00 00 00 00 00 00 00 00 00 00 14 0f 0a 05 00 00 00 00 00 00 00 00 00 05 0a 0f 00 80 00 80 00 80 00 80 00 80 00 80 00 80 00 80 00 80 00 80 00 80 00 80 00 80 00 80 00 80 00 80 00 80 00 80 80 40 10 00 00 00 00 00 00 00 00 00 00 00 00 00 14 0f 0a 05 00 00 00 00 00 00 00 00 00 05 0a 0f 00 80 00 80 00 80 00 80 00 80 00 80 00 80 00 80 00 80 00 80 00 80 00 80 00 80 00 80 00 80 00 80 00 80 00 80 80 40 10 00 00 00 00 00 00 00 00 00 00 00 00 00 14 0f 0a 05 00 00 00 00 00 00 00 00 00 05 0a 0f 00 80 00 80 00 80 00 80 00 80 00 80 00 80 00 80 00 80 00 80 00 80 00 80 00 80 00 80 00 80 00 80 00 80 00 80 80 40 10 00 00 00 00 00 00 00 00 00 00 00 00 00 14 0f 0a 05 00 00 00 00 00 00 00 00 00 05 0a 0f 00 80 00 80 00 80 00 80 00 80 00 80 00 80 00 80 00 80 00 80 00 80 00 80 00 80 00 80 00 80 00 80 00 80 00 80 80 40 10 00 00 00 00 00 00 00 00 00 00 00 00 00 14 0f 0a 05 00 00 00 00 00 00 00 00 00 05 0a 0f 00 80 00 80 00 80 00 80 00 80 00 80 00 80 00 80 00 80 00 80 00 80 00 80 00 80 00 80 00 80 00 80 00 80 00 80 80 40 10 00 00 00 00 00 00 00 00 00 00 00 00 00 14 0f 0a 05 00 00 00 00 00 00 00 00 00 05 0a 0f 00 80 00 80 00 80 00 80 00 80 00 80 00 80 00 80 00 80 00 80 00 80 00 80 00 80 00 80 00 80 00 80 00 80 00 80 80 40 10 00 00 00 00 00 00 00 00 00 00 00 00 00 14 0f 0a 05 00 00 00 00 00 00 00 00 00 05 0a 0f 00 80 00 80 00 80 00 80 00 80 00 80 00 80 00 80 00 80 00 80 00 80 00 80 00 80 00 80 00 80 00 80 00 80 00 80 80 40 10 00 00 00 00 00 00 00 00 00 00 00 00 00 14 0f 0a 05 00 00 00 00 00 00 00 00 00 05 0a 0f 00 80 00 80 00 80 00 80 00 80 00 80 00 80 00 80 00 80 00 80 00 80 00 80 00 80 00 80 00 70 00 60 00 50 00 80 80 40 10 00 00 00 00 00 00 00 00 00 00 00 00 00 14 0f 0a 05 00 00 00 00 00 00 00 00 00 05 0a 0f 00 80 00 80 00 80 00 80 00 80 00 80 00 80 00 80 00 80 00 80 00 80 00 80 00 80 00 80 00 70 00 60 00 50 00 80 80 40 10 00 00 00 00 00 00 00 00 00 00 00 00 00 14 0f 0a 05 00 00 00 00 00 00 00 00 00 05 0a 0f 00 80 00 80 00 80 00 80 00 80 00 80 00 80 00 80 00 80 00 80 00 80 00 80 00 80 00 80 00 70 00 60 00 50 00 80 80 40 10 00 00 00 00 00 00 00 00 00 00 00 00 00 14 0f 0a 05 00 00 00 00 00 00 00 00 00 05 0a 0f 00 80 00 80 00 80 00 80 00 80 00 80 00 80 00 80 00 80 00 80 00 80 00 80 00 80 00 80 00 80 00 80 00 80 00 80 80 40 10 00 00 00 00 00 00 00 00 00 00 00 00 00 14 0f 0a 05 00 00 00 00 00 00 00 00 00 05 0a 0f 00 80 00 80 00 80 00 80 00 80 00 80 00 80 00 80 00 80 00 80 00 80 00 80 00 80 00 80 00 80 00 80 00 80 00 80 80 40 10 00 00 00 00 00 00 00 00 00 00 00 00 00 14 0f 0a 05 00 00 00 00 00 00 00 00 00 05 0a 0f 00 80 00 80 00 80 00 80 00 80 00 80 00 80 00 80 00 80 00 80 00 80 00 80 00 80 00 80 00 80 00 80 00 80 00 80 80 40 10 00 00 00 00 00 00 00 00 00 00 00 00 00 14 0f 0a 05 00 00 00 00 00 00 00 00 00 05 0a 0f 00 80 00 80 00 80 00 80 00 80 00 80 00 80 00 80 00 80 00 80 00 80 00 80 00 80 00 80 00 80 00 80 00 80 00];
		};
		iq_contrast {
			size = [b8 00 00 00];
			data = [01 00 00 00 01 00 00 00 00 00 00 00 80 00 00 00 00 00 00 00 00 00 80 14 14 14 14 14 14 14 14 14 80 14 14 14 14 14 14 14 14 14 80 14 14 14 14 14 14 14 14 14 80 14 14 14 14 14 14 14 14 14 84 14 14 14 14 14 14 14 14 14 84 14 14 14 14 14 14 14 14 14 84 0a 0a 0a 0a 0a 0a 0a 0a 0a 84 0a 0a 0a 0a 0a 0a 0a 0a 0a 87 0a 0a 0a 0a 0a 0a 0a 0a 0a 87 0a 0a 0a 0a 0a 0a 0a 0a 0a 84 0a 0a 0a 0a 0a 0a 0a 0a 0a 84 0a 0a 0a 0a 0a 0a 0a 0a 0a 80 00 00 00 00 00 00 00 00 00 80 00 00 00 00 00 00 00 00 00 80 00 00 00 00 00 00 00 00 00 80 00 00 00 00 00 00 00 00 00 00 00];
		};
		iq_edge {
			size = [28 06 00 00];
			data = [01 00 00 00 00 00 00 00 80 00 00 00 31 00 00 00 32 e0 10 00 30 57 7a 9a b7 dd ff ff e0 c0 aa 9a 90 88 80 20 2d 35 40 40 40 40 40 40 40 40 40 40 34 2c 26 80 80 80 80 80 80 80 80 80 80 80 80 80 80 80 80 80 80 80 80 80 80 80 80 00 80 00 00 00 80 00 00 00 80 00 00 00 08 00 00 00 00 00 00 00 00 00 00 00 10 00 00 00 08 00 00 00 28 00 00 00 f0 00 00 00 00 01 00 00 20 50 00 00 00 01 00 00 00 01 00 00 00 00 00 00 80 00 00 00 00 00 00 00 02 00 00 00 00 00 00 00 00 02 00 00 00 00 00 00 05 00 00 00 04 00 00 00 8c 00 00 00 8c 00 00 00 10 00 00 00 10 00 00 00 00 00 00 00 10 00 00 00 35 00 00 00 3e 00 00 00 82 00 00 00 92 00 00 00 20 50 00 00 00 01 00 00 00 01 00 00 00 00 00 00 80 00 00 00 00 00 00 00 05 00 00 00 00 00 00 00 00 02 00 00 00 00 00 00 05 00 00 00 04 00 00 00 8c 00 00 00 8c 00 00 00 10 00 00 00 10 00 00 00 00 00 00 00 10 00 00 00 32 00 00 00 3c 00 00 00 82 00 00 00 92 00 00 00 20 50 00 00 00 01 00 00 00 01 00 00 00 00 00 00 80 00 00 00 00 00 00 00 05 00 00 00 00 00 00 00 00 02 00 00 00 00 00 00 05 00 00 00 04 00 00 00 8c 00 00 00 8c 00 00 00 10 00 00 00 0c 00 00 00 00 00 00 00 10 00 00 00 3c 00 00 00 46 00 00 00 82 00 00 00 92 00 00 00 20 50 00 00 00 01 00 00 00 01 00 00 00 00 00 00 80 00 00 00 00 00 00 00 04 00 00 00 00 00 00 00 00 02 00 00 00 00 00 00 05 00 00 00 04 00 00 00 8c 00 00 00 8c 00 00 00 0c 00 00 00 08 00 00 00 00 00 00 00 0c 00 00 00 3c 00 00 00 46 00 00 00 9a 00 00 00 aa 00 00 00 20 50 00 00 00 01 00 00 00 01 00 00 00 00 00 00 80 00 00 00 00 00 00 00 04 00 00 00 00 00 00 00 00 02 00 00 00 00 00 00 05 00 00 00 04 00 00 00 8c 00 00 00 8c 00 00 00 08 00 00 00 08 00 00 00 00 00 00 00 08 00 00 00 46 00 00 00 50 00 00 00 9a 00 00 00 aa 00 00 00 20 50 00 00 00 01 00 00 00 01 00 00 00 00 00 00 80 00 00 00 00 00 00 00 04 00 00 00 00 00 00 00 00 02 00 00 00 00 00 00 05 00 00 00 04 00 00 00 8c 00 00 00 8c 00 00 00 04 00 00 00 04 00 00 00 00 00 00 00 08 00 00 00 64 00 00 00 6e 00 00 00 33 01 00 00 43 01 00 00 20 50 00 00 00 01 00 00 00 01 00 00 00 00 00 00 80 00 00 00 00 00 00 00 04 00 00 00 00 00 00 00 00 02 00 00 00 00 00 00 05 00 00 00 04 00 00 00 8c 00 00 00 8c 00 00 00 02 00 00 00 00 00 00 00 00 00 00 00 04 00 00 00 82 00 00 00 8c 00 00 00 33 01 00 00 43 01 00 00 20 50 00 00 00 01 00 00 00 01 00 00 00 00 00 00 80 00 00 00 00 00 00 00 02 00 00 00 00 00 00 00 00 02 00 00 00 00 00 00 05 00 00 00 04 00 00 00 80 00 00 00 80 00 00 00 02 00 00 00 00 00 00 00 00 00 00 00 04 00 00 00 aa 00 00 00 b4 00 00 00 33 01 00 00 43 01 00 00 20 50 00 00 00 01 00 00 00 01 00 00 00 00 00 00 80 00 00 00 02 00 00 00 02 00 00 00 00 00 00 00 00 02 00 00 00 00 00 00 05 00 00 00 04 00 00 00 80 00 00 00 80 00 00 00 00 00 00 00 00 00 00 00 00 00 00 00 04 00 00 00 f2 00 00 00 04 01 00 00 33 01 00 00 43 01 00 00 20 50 00 00 00 01 00 00 00 01 00 00 00 00 00 00 80 00 00 00 03 00 00 00 02 00 00 00 00 00 00 00 00 02 00 00 00 00 00 00 05 00 00 00 04 00 00 00 80 00 00 00 80 00 00 00 00 00 00 00 00 00 00 00 00 00 00 00 04 00 00 00 88 00 00 00 a8 00 00 00 33 01 00 00 43 01 00 00 20 50 00 00 00 01 00 00 00 01 00 00 00 00 00 00 80 00 00 00 03 00 00 00 02 00 00 00 00 00 00 00 00 02 00 00 00 00 00 00 05 00 00 00 04 00 00 00 6e 00 00 00 6e 00 00 00 00 00 00 00 00 00 00 00 00 00 00 00 04 00 00 00 18 01 00 00 22 01 00 00 33 01 00 00 43 01 00 00 20 50 00 00 00 01 00 00 00 01 00 00 00 00 00 00 80 00 00 00 05 00 00 00 02 00 00 00 00 00 00 00 00 02 00 00 00 00 00 00 05 00 00 00 04 00 00 00 6e 00 00 00 6e 00 00 00 00 00 00 00 00 00 00 00 00 00 00 00 00 00 00 00 88 00 00 00 a8 00 00 00 33 01 00 00 43 01 00 00 20 50 00 00 00 01 00 00 00 01 00 00 00 00 00 00 80 00 00 00 05 00 00 00 02 00 00 00 00 00 00 00 00 02 00 00 00 00 00 00 05 00 00 00 04 00 00 00 60 00 00 00 60 00 00 00 00 00 00 00 00 00 00 00 00 00 00 00 04 00 00 00 88 00 00 00 a8 00 00 00 33 01 00 00 43 01 00 00 20 50 00 00 00 01 00 00 00 01 00 00 00 00 00 00 80 00 00 00 03 00 00 00 02 00 00 00 00 00 00 00 00 02 00 00 00 00 00 00 05 00 00 00 04 00 00 00 60 00 00 00 60 00 00 00 00 00 00 00 00 00 00 00 00 00 00 00 04 00 00 00 88 00 00 00 a8 00 00 00 33 01 00 00 43 01 00 00 20 50 00 00 00 01 00 00 00 01 00 00 00 00 00 00 80 00 00 00 03 00 00 00 02 00 00 00 00 00 00 00 00 02 00 00 00 00 00 00 05 00 00 00 04 00 00 00 60 00 00 00 60 00 00 00 00 00 00 00 00 00 00 00 00 00 00 00 04 00 00 00 88 00 00 00 a8 00 00 00 33 01 00 00 43 01 00 00 20 50 00 00 00 01 00 00 00 01 00 00 00 00 00 00 80 00 00 00 03 00 00 00 02 00 00 00 00 00 00 00 00 02 00 00 00 00 00 00 05 00 00 00 04 00 00 00 60 00 00 00 60 00 00 00 00 00 00 00 00 00 00 00 00 00 00 00 04 00 00 00 88 00 00 00 a8 00 00 00 33 01 00 00 43 01 00 00 20 50 00 00 00 01 00 00 00 01 00 00 00 00 00 00 80 00 00 00 03 00 00 00 02 00 00 00 00 00 00 00 00 02 00 00 00 00 00 00 05 00 00 00 04 00 00 00];
		};
		iq_3dnr {
			size = [54 0d 00 00];
			data = [01 00 00 00 00 00 00 00 00 00 00 00 00 0f 40 00 40 00 00 00 80 00 80 00 80 00 c8 00 c8 00 04 04 03 04 04 04 04 04 05 05 06 06 07 07 08 08 80 04 00 00 00 00 00 00 00 00 00 00 00 00 00 00 00 00 00 00 00 00 00 00 00 00 00 00 00 00 00 00 00 00 00 00 00 00 00 00 00 00 00 00 00 00 00 00 00 00 00 00 00 00 00 00 00 00 08 10 04 10 20 06 c8 00 01 01 01 01 00 00 00 00 00 00 00 00 00 00 00 00 00 00 10 20 30 40 80 40 00 01 00 00 00 01 00 00 10 10 10 10 10 10 10 10 10 10 10 10 08 10 40 40 10 08 00 06 0c 18 28 4c 60 70 80 40 00 06 0c 18 28 4c 60 70 80 40 00 04 01 ff 40 00 40 00 40 00 40 00 40 00 40 00 40 00 40 00 00 00 00 00 00 00 00 00 00 00 00 0f 20 00 20 00 00 00 40 00 40 00 40 00 50 00 50 00 04 04 03 04 04 04 04 04 06 06 06 06 06 07 07 08 80 06 90 01 90 01 90 01 90 01 f4 01 14 05 14 05 14 05 06 05 05 06 04 04 04 04 32 00 28 00 28 00 28 00 1e 00 1e 00 1e 00 1e 00 32 00 28 00 28 00 28 00 32 00 32 00 32 00 32 00 08 10 03 10 20 03 c8 00 01 01 01 01 00 00 00 00 00 00 00 00 00 00 00 00 00 00 04 08 10 20 80 40 f4 01 00 00 f4 01 00 00 10 10 20 20 10 10 10 10 10 10 10 10 00 0a 14 20 20 00 00 0b 13 1b 23 2b 31 3a 80 40 00 0d 15 1e 23 29 31 3c 40 20 00 04 01 ff 40 00 40 00 40 00 40 00 40 00 40 00 40 00 40 00 00 00 00 00 00 00 00 00 00 00 00 0f 50 00 50 00 00 00 a0 00 a0 00 a0 00 e6 00 e6 00 04 04 03 04 04 04 04 04 06 06 06 06 06 07 07 08 80 06 90 01 90 01 90 01 90 01 f4 01 14 05 14 05 14 05 08 07 07 08 06 06 06 06 46 00 3c 00 3c 00 3c 00 32 00 32 00 32 00 32 00 32 00 3c 00 40 00 42 00 44 00 44 00 46 00 46 00 08 10 03 10 20 03 c8 00 01 01 01 01 00 00 00 00 00 00 00 00 00 00 00 00 00 00 04 08 10 20 80 40 f4 01 00 00 f4 01 00 00 10 10 20 20 10 10 10 10 10 10 10 10 00 0f 1e 20 20 00 00 0b 13 1b 23 2b 31 3a 80 40 00 0d 15 1e 23 29 31 3c 40 20 00 04 01 ff 40 00 40 00 40 00 40 00 40 00 40 00 40 00 40 00 00 00 00 00 00 00 00 00 00 00 00 0f 50 00 50 00 00 00 a0 00 a0 00 a0 00 e6 00 e6 00 04 04 03 04 04 04 04 04 06 06 06 06 06 07 07 08 80 04 90 01 90 01 90 01 90 01 f4 01 14 05 14 05 14 05 0b 0a 0a 0b 08 08 08 08 50 00 46 00 46 00 46 00 3c 00 3c 00 3c 00 3c 00 32 00 3c 00 40 00 42 00 44 00 44 00 46 00 46 00 08 10 03 10 20 03 c8 00 01 01 01 01 00 00 00 00 00 00 00 00 00 00 00 00 00 00 10 20 40 50 80 40 e8 03 00 00 e8 03 00 00 10 10 20 20 10 10 10 10 10 10 10 10 00 28 32 40 40 00 00 0b 13 1b 23 2b 31 3a 80 40 00 0d 15 1e 23 29 31 3c 40 20 00 04 01 ff 40 00 40 00 40 00 40 00 40 00 40 00 40 00 40 00 00 00 00 00 00 00 00 00 00 00 00 0f 50 00 50 00 00 00 a0 00 a0 00 a0 00 e6 00 e6 00 04 04 03 04 04 04 04 04 06 06 06 06 06 07 07 08 80 04 90 01 90 01 90 01 90 01 f4 01 14 05 14 05 14 05 0d 0c 0c 0d 0a 0a 0a 0a 50 00 46 00 46 00 46 00 3c 00 3c 00 3c 00 3c 00 32 00 3c 00 40 00 42 00 44 00 44 00 46 00 46 00 08 10 03 10 20 03 c8 00 01 01 01 01 00 00 00 00 00 00 00 00 00 00 00 00 00 00 10 20 40 50 80 40 e8 03 00 00 e8 03 00 00 10 10 20 20 10 10 10 10 10 10 10 10 00 50 64 40 40 00 00 0b 13 1b 23 2b 31 3a 80 40 00 0d 15 1e 23 29 31 3c 80 40 00 04 01 ff 40 00 40 00 40 00 40 00 40 00 40 00 40 00 40 00 00 00 00 00 00 00 00 00 00 00 00 0f 50 00 50 00 00 00 a0 00 a0 00 a0 00 e6 00 e6 00 04 04 03 04 04 04 04 04 06 06 06 06 06 07 07 08 80 04 90 01 90 01 90 01 90 01 f4 01 14 05 14 05 14 05 0d 0c 0c 0d 0a 0a 0a 0a 50 00 46 00 46 00 46 00 3c 00 3c 00 3c 00 3c 00 32 00 3c 00 40 00 42 00 44 00 44 00 46 00 46 00 08 10 03 10 20 03 c8 00 01 01 01 01 00 00 00 00 00 00 00 00 00 00 00 00 00 00 10 20 40 50 80 40 e8 03 00 00 e8 03 00 00 10 10 20 20 10 10 10 10 10 10 10 10 00 50 64 40 40 00 00 0b 13 1b 23 2b 31 3a 80 40 00 0d 15 1e 23 29 31 3c 40 20 00 04 01 ff 40 00 40 00 40 00 40 00 40 00 40 00 40 00 40 00 00 00 00 00 00 00 00 00 00 00 00 0f 96 00 96 00 00 00 5e 01 5e 01 5e 01 26 02 26 02 04 04 03 04 04 04 04 04 06 06 06 06 06 07 07 08 9e 04 90 01 90 01 90 01 90 01 f4 01 14 05 14 05 14 05 12 11 11 12 0f 0f 0f 0f 78 00 78 00 82 00 82 00 82 00 82 00 82 00 82 00 32 00 3c 00 40 00 42 00 44 00 44 00 46 00 46 00 08 10 03 10 20 03 c8 00 01 01 01 01 00 00 00 00 00 00 00 00 00 00 00 00 00 00 10 20 40 50 80 40 e8 03 00 00 e8 03 00 00 10 10 20 20 10 10 10 10 10 10 10 10 00 82 64 80 28 00 00 0b 13 1b 23 2b 31 3a 80 40 00 0d 15 1e 23 29 31 3c 80 40 00 04 01 ff 40 00 40 00 40 00 40 00 40 00 40 00 40 00 40 00 00 00 00 00 00 00 00 00 00 00 00 0f 96 00 96 00 00 00 5e 01 5e 01 5e 01 26 02 26 02 04 04 03 04 04 04 04 04 06 06 06 06 06 07 07 08 9e 05 90 01 90 01 90 01 90 01 f4 01 14 05 14 05 14 05 14 13 14 1c 15 15 15 15 78 00 78 00 82 00 82 00 82 00 82 00 82 00 82 00 32 00 3c 00 40 00 42 00 44 00 44 00 46 00 46 00 08 10 03 10 20 03 c8 00 01 01 01 01 00 00 00 00 00 00 00 00 00 00 00 00 00 00 40 50 64 64 80 40 e8 03 00 00 e8 03 00 00 10 10 20 20 10 10 10 10 10 10 10 10 00 96 c8 c8 40 00 00 08 0e 15 20 24 2f 3a 80 40 00 08 0d 0e 13 15 16 1c 80 40 00 04 01 ff 40 00 40 00 40 00 40 00 40 00 40 00 40 00 40 00 00 00 00 00 00 00 00 00 00 00 00 0f 96 00 96 00 00 00 5e 01 5e 01 5e 01 26 02 26 02 04 04 03 04 04 04 04 04 06 06 06 06 06 07 07 08 9e 05 90 01 90 01 90 01 90 01 f4 01 14 05 14 05 14 05 14 13 14 1c 15 15 15 15 78 00 78 00 82 00 82 00 82 00 82 00 82 00 82 00 32 00 3c 00 40 00 42 00 44 00 44 00 46 00 46 00 08 10 03 10 20 03 c8 00 01 01 01 01 00 00 00 00 00 00 00 00 00 00 00 00 00 00 40 50 64 64 80 40 e8 03 00 00 e8 03 00 00 10 10 20 20 10 10 10 10 10 10 10 10 00 96 c8 c8 40 00 00 08 0e 15 20 24 2f 3a 80 40 00 08 0d 0e 13 15 16 1c 80 40 00 04 01 ff 40 00 40 00 40 00 40 00 40 00 40 00 40 00 40 00 00 00 00 00 00 00 00 00 00 00 00 0f 96 00 96 00 00 00 5e 01 5e 01 5e 01 26 02 26 02 04 04 03 04 04 04 04 04 06 06 06 06 06 07 07 08 9e 03 90 01 90 01 90 01 90 01 f4 01 14 05 14 05 14 05 1e 23 19 1c 23 23 22 22 96 00 96 00 b4 00 b4 00 b4 00 b4 00 b4 00 b4 00 32 00 3c 00 40 00 42 00 44 00 44 00 46 00 46 00 08 10 03 10 20 03 c8 00 01 01 01 01 00 00 00 00 00 00 00 00 00 00 00 00 00 00 00 00 00 00 80 40 08 07 00 00 b8 0b 00 00 10 10 20 20 10 10 10 10 10 10 10 10 00 50 c8 c8 40 00 00 04 08 10 20 30 40 50 80 40 00 08 0d 0e 13 15 16 1c 80 40 00 04 01 ff 40 00 40 00 40 00 40 00 40 00 40 00 40 00 40 00 00 00 00 00 00 00 00 00 00 00 00 0f 2c 01 2c 01 00 00 58 02 58 02 58 02 20 03 20 03 03 03 03 03 03 03 03 03 04 05 06 06 06 07 07 08 80 04 90 01 90 01 90 01 90 01 f4 01 f4 01 f4 01 f4 01 20 21 21 21 1d 1d 1d 1d 0e 01 0e 01 22 01 22 01 2c 01 2c 01 2c 01 2c 01 32 00 3c 00 40 00 42 00 44 00 44 00 46 00 46 00 0a 0e 03 10 20 03 c8 00 01 01 01 01 00 00 00 00 00 00 00 00 00 00 00 00 00 00 3c 3c 5a 5a 20 10 08 07 00 00 b8 0b 00 00 10 10 20 20 10 10 10 10 10 10 10 10 00 50 78 c8 18 00 00 03 09 13 1b 1e 29 32 80 40 00 08 0d 0e 13 15 16 1c 80 40 00 04 01 ff 40 00 40 00 40 00 40 00 40 00 40 00 40 00 40 00 00 00 00 00 00 00 00 00 00 00 00 0f c8 00 c8 00 00 00 90 01 90 01 90 01 58 02 58 02 03 03 02 03 03 03 03 03 04 05 06 06 06 07 07 08 80 04 90 01 90 01 90 01 90 01 f4 01 f4 01 f4 01 f4 01 22 24 25 25 22 22 22 22 fa 00 e6 00 fa 00 fa 00 04 01 04 01 04 01 04 01 46 00 50 00 50 00 50 00 50 00 46 00 46 00 46 00 0a 0e 05 10 20 04 c8 00 01 01 01 01 00 00 00 00 00 00 00 00 00 00 00 00 00 00 3c 3c 5a 5a 20 10 08 07 00 00 b8 0b 00 00 10 10 20 20 10 10 10 10 10 10 10 10 00 50 78 c8 18 00 00 05 0b 13 1b 1e 29 32 80 40 00 08 0d 0e 13 15 16 1c 80 40 00 04 01 ff 40 00 40 00 40 00 40 00 40 00 40 00 40 00 40 00 00 00 00 00 00 00 00 00 00 00 00 0f c8 00 c8 00 00 00 90 01 90 01 90 01 58 02 58 02 03 03 03 03 03 03 03 03 07 05 05 05 0f 0f 0f 0f af 03 00 04 4c 04 b0 04 14 05 14 05 14 05 14 05 14 05 19 32 32 32 23 23 14 14 50 00 6e 00 6e 00 6e 00 8c 00 96 00 a0 00 a0 00 3c 00 5a 00 5a 00 5a 00 44 00 50 00 50 00 5a 00 10 14 03 10 20 04 c8 00 01 01 01 01 00 00 00 00 00 00 00 00 00 00 00 00 00 00 8c 96 a0 aa 80 40 b8 0b 00 00 70 17 00 00 10 10 20 20 10 10 10 10 10 10 10 10 00 40 80 ff 10 06 00 06 0d 15 1c 26 2f 3a 80 40 00 06 0b 0b 13 18 21 34 80 40 00 04 01 ff 40 00 40 00 40 00 40 00 40 00 40 00 40 00 40 00 00 00 00 00 00 00 00 00 00 00 00 0f 80 00 80 00 00 00 00 01 00 01 00 01 00 02 00 02 04 04 03 04 04 04 04 04 08 09 09 0a 0a 0a 0b 0b 96 03 00 02 00 02 00 02 00 02 00 02 00 02 00 02 00 02 18 18 17 15 16 16 16 16 5a 00 5a 00 5a 00 5a 00 5a 00 5a 00 5a 00 5a 00 3c 00 3c 00 3c 00 3c 00 3c 00 3c 00 3c 00 3c 00 08 10 14 10 20 02 c8 00 01 01 01 01 00 00 00 00 00 00 00 00 00 00 00 00 00 00 64 6e 78 82 80 40 b0 04 00 00 d0 07 00 00 14 10 10 10 14 18 18 10 10 10 10 10 00 20 80 ff 20 02 00 01 01 01 01 02 03 04 80 40 00 06 0b 0b 13 18 21 34 80 40 00 04 01 ff 40 00 40 00 40 00 40 00 40 00 40 00 40 00 40 00 00 00 00 00 00 00 00 00 00 00 00 0f 80 00 80 00 00 00 00 01 00 01 00 01 00 02 00 02 04 04 03 04 04 04 04 04 08 09 09 0a 0a 0a 0b 0b 96 03 00 02 00 02 00 02 00 02 00 02 00 02 00 02 00 02 18 18 17 15 16 16 16 16 5a 00 5a 00 5a 00 5a 00 5a 00 5a 00 5a 00 5a 00 3c 00 3c 00 3c 00 3c 00 3c 00 3c 00 3c 00 3c 00 08 10 14 10 20 02 c8 00 01 01 01 01 00 00 00 00 00 00 00 00 00 00 00 00 00 00 64 6e 78 82 80 40 b0 04 00 00 d0 07 00 00 14 10 10 10 14 18 18 10 10 10 10 10 00 20 80 ff 20 02 00 01 01 01 01 02 03 04 80 40 00 06 0b 0b 13 18 21 34 80 40 00 04 01 ff 40 00 40 00 40 00 40 00 40 00 40 00 40 00 40 00 00 00 00 00 00 00 00 00 00 00 00 0f 80 00 80 00 00 00 00 01 00 01 00 01 00 02 00 02 04 04 03 04 04 04 04 04 08 09 09 0a 0a 0a 0b 0b 96 03 00 02 00 02 00 02 00 02 00 02 00 02 00 02 00 02 18 18 17 15 16 16 16 16 5a 00 5a 00 5a 00 5a 00 5a 00 5a 00 5a 00 5a 00 3c 00 3c 00 3c 00 3c 00 3c 00 3c 00 3c 00 3c 00 08 10 14 10 20 02 c8 00 01 01 01 01 00 00 00 00 00 00 00 00 00 00 00 00 00 00 64 6e 78 82 80 40 b0 04 00 00 d0 07 00 00 14 10 10 10 14 18 18 10 10 10 10 10 00 20 80 ff 20 02 00 01 01 01 01 02 03 04 80 40 00 06 0b 0b 13 18 21 34 80 40 00 04 01 ff 40 00 40 00 40 00 40 00 40 00 40 00 40 00 40 00 00 00 00 00 00 00 00 00 00 00 00 0f 80 00 80 00 00 00 00 01 00 01 00 01 00 02 00 02 04 04 03 04 04 04 04 04 08 09 09 0a 0a 0a 0b 0b 96 03 00 02 00 02 00 02 00 02 00 02 00 02 00 02 00 02 18 18 17 15 16 16 16 16 5a 00 5a 00 5a 00 5a 00 5a 00 5a 00 5a 00 5a 00 3c 00 3c 00 3c 00 3c 00 3c 00 3c 00 3c 00 3c 00 08 10 14 10 20 02 c8 00 01 01 01 01 00 00 00 00 00 00 00 00 00 00 00 00 00 00 64 6e 78 82 80 40 b0 04 00 00 d0 07 00 00 14 10 10 10 14 18 18 10 10 10 10 10 00 20 80 ff 20 02 00 01 01 01 01 02 03 04 80 40 00 06 0b 0b 13 18 21 34 80 40 00 04 01 ff 40 00 40 00 40 00 40 00 40 00 40 00 40 00 40 00 00 00 00 00 00 00 00 00 00 00];
		};
		iq_pfr {
			size = [d0 00 00 00];
			data = [00 00 00 00 00 00 00 00 00 00 00 08 70 e8 ff ff ff ff ff ff ff 00 00 00 01 00 00 00 af 00 00 00 91 00 00 00 01 00 00 00 91 00 00 00 af 00 00 00 00 00 00 00 50 00 00 00 74 00 00 00 00 00 00 00 74 00 00 00 50 00 00 00 e0 00 00 00 2c 01 00 00 e0 00 00 00 2c 01 00 00 e0 00 00 00 2c 01 00 00 e0 00 00 00 2c 01 00 00 e0 00 00 00 2c 01 00 00 e0 00 00 00 2c 01 00 00 e0 00 00 00 2c 01 00 00 e0 00 00 00 2c 01 00 00 e0 00 00 00 2c 01 00 00 e0 00 00 00 2c 01 00 00 e0 00 00 00 2c 01 00 00 e0 00 00 00 2c 01 00 00 e0 00 00 00 2c 01 00 00 e0 00 00 00 2c 01 00 00 e0 00 00 00 2c 01 00 00 e0 00 00 00 2c 01 00 00 e0 00 00 00 2c 01 00 00];
		};
		iq_wdr {
			size = [88 01 00 00];
			data = [01 00 00 00 00 00 00 00 20 00 00 00 12 00 00 00 05 00 00 00 03 00 00 00 80 40 80 00 00 00 b5 0f b0 0f ab 0f a5 0f a0 0f 9a 0f 93 0f 8c 0f 85 0f 7d 0f 74 0f 6c 0f 62 0f 58 0f 4e 0f 43 0f 37 0f 2a 0f 1d 0f 0f 0f 00 0f f1 0e e0 0e cf 0e bc 0e a9 0e 94 0e 7f 0e 68 0e 50 0e 37 0e 1c 0e 01 0e e4 0d c5 0d a5 0d 84 0d 62 0d 3d 0d 18 0d f0 0c c8 0c 9d 0c 71 0c 44 0c 15 0c e4 0b b2 0b 7f 0b 4a 0b 14 0b dc 0a a4 0a 6a 0a 2f 0a f3 09 b6 09 78 09 3a 09 fb 08 bc 08 7c 08 3c 08 fc 07 bc 07 bc 07 bf 06 cc 05 ea 04 1c 04 66 03 c9 02 43 02 d3 01 76 01 2b 01 ee 00 bc 00 95 00 76 00 5d 00 49 00 00 00 40 00 00 00 40 00 00 00 20 00 00 00 ff 00 00 00 40 00 00 00 10 00 00 00 ff 00 00 00 30 00 00 00 08 00 00 00 ff 00 00 00 30 00 00 00 00 00 00 00 ff 00 00 00 20 00 00 00 00 00 00 00 ff 00 00 00 20 00 00 00 00 00 00 00 ff 00 00 00 20 00 00 00 00 00 00 00 ff 00 00 00 20 00 00 00 00 00 00 00 ff 00 00 00 20 00 00 00 00 00 00 00 ff 00 00 00 10 00 00 00 00 00 00 00 ff 00 00 00 10 00 00 00 00 00 00 00 ff 00 00 00 00 00 00 00 00 00 00 00 ff 00 00 00 00 00 00 00 00 00 00 00 ff 00 00 00 00 00 00 00 00 00 00 00 ff 00 00 00 00 00 00 00 00 00 00 00 ff 00 00 00 00 00 00 00 00 00 00 00 ff 00 00 00];
		};
		iq_wdr_enh {
			size = [48 00 00 00];
			data = [01 00 00 00 80 00 00 00 80 00 00 00 80 00 00 00 80 00 00 00 80 00 00 00 80 00 00 00 80 00 00 00 80 00 00 00 80 00 00 00 80 00 00 00 80 00 00 00 80 00 00 00 80 00 00 00 80 00 00 00 80 00 00 00 80 00 00 00 80 00 00 00];
		};
		iq_defog {
			size = [1c 00 00 00];
			data = [00 00 00 00 01 00 00 00 ff ff ff ff ff ff ff ff ff ff ff ff ff ff ff ff ff 00 00 00];
		};
		iq_shdr {
			size = [64 02 00 00];
			data = [00 00 00 00 01 00 00 00 00 00 00 00 01 00 00 00 00 0c 09 00 c0 00 06 00 02 00 00 00 00 0c 09 00 c0 00 06 00 00 00 02 04 08 0a 0c 0e 10 0e 0c 0a 08 06 04 02 00 00 00 00 00 00 00 00 08 00 00 00 00 00 00 00 00 00 00 00 00 00 00 00 00 00 00 00 01 00 00 00 9e 26 00 00 71 3c 00 00 b9 4b 00 00 7e 57 00 00 12 61 00 00 b6 67 00 00 3f 6d 00 00 f0 70 00 00 4c 74 00 00 66 77 00 00 47 7a 00 00 f9 7c 00 00 84 7f 00 00 ed 81 00 00 38 84 00 00 68 86 00 00 82 88 00 00 86 8a 00 00 79 8c 00 00 5a 8e 00 00 2d 90 00 00 f2 91 00 00 aa 93 00 00 57 95 00 00 f9 96 00 00 91 98 00 00 20 9a 00 00 a6 9b 00 00 25 9d 00 00 9c 9e 00 00 0c a0 00 00 76 a1 00 00 da a2 00 00 38 a4 00 00 91 a5 00 00 e4 a6 00 00 33 a8 00 00 7d a9 00 00 c3 aa 00 00 04 ac 00 00 42 ad 00 00 7c ae 00 00 b2 af 00 00 e5 b0 00 00 14 b2 00 00 41 b3 00 00 6a b4 00 00 91 b5 00 00 b4 b6 00 00 d6 b7 00 00 f4 b8 00 00 10 ba 00 00 2a bb 00 00 41 bc 00 00 57 bd 00 00 6a be 00 00 7b bf 00 00 8a c0 00 00 98 c1 00 00 a4 c2 00 00 ad c3 00 00 b5 c4 00 00 bb c5 00 00 c0 c6 00 00 c0 c6 00 00 c4 ca 00 00 b1 ce 00 00 8a d2 00 00 52 d6 00 00 09 da 00 00 b2 dd 00 00 4d e1 00 00 dd e4 00 00 60 e8 00 00 da eb 00 00 4a ef 00 00 b1 f2 00 00 10 f6 00 00 66 f9 00 00 b6 fc 00 00 ff ff 00 00 28 00 32 00 3c 00 46 00 50 00 50 00 28 00 32 00 3c 00 46 00 50 00 50 00 28 00 32 00 3c 00 46 00 50 00 50 00 28 00 32 00 3c 00 46 00 50 00 50 00 28 00 32 00 3c 00 46 00 50 00 50 00 28 00 32 00 3c 00 46 00 50 00 50 00 28 00 32 00 3c 00 46 00 50 00 50 00 28 00 32 00 3c 00 46 00 50 00 50 00 28 00 32 00 3c 00 46 00 50 00 50 00 28 00 32 00 3c 00 46 00 50 00 50 00 28 00 32 00 3c 00 46 00 50 00 50 00 28 00 32 00 3c 00 46 00 50 00 50 00 28 00 32 00 3c 00 46 00 50 00 50 00 28 00 32 00 3c 00 46 00 50 00 50 00 28 00 32 00 3c 00 46 00 50 00 50 00 28 00 32 00 3c 00 46 00 50 00 50 00 28 00 32 00 3c 00 46 00 50 00 50 00];
		};
		iq_companding {
			size = [18 01 00 00];
			data = [00 02 00 00 00 03 00 00 00 0a 00 00 ff 0f 00 00 ff 0f 00 00 ff 0f 00 00 ff 0f 00 00 ff 0f 00 00 ff 0f 00 00 ff 0f 00 00 ff 0f 00 00 00 00 00 00 00 01 00 00 00 02 00 00 00 08 00 00 00 08 00 00 00 08 00 00 00 08 00 00 00 08 00 00 00 08 00 00 00 08 00 00 00 08 00 00 00 08 00 00 04 00 00 00 05 00 00 00 06 00 00 00 08 00 00 00 08 00 00 00 08 00 00 00 08 00 00 00 08 00 00 00 08 00 00 00 08 00 00 00 08 00 00 00 08 00 00 00 0a 00 00 00 0b 00 00 00 0c 00 00 00 0d 00 00 00 0e 00 00 00 0f 00 00 00 10 00 00 00 10 00 00 00 10 00 00 00 10 00 00 00 10 00 00 00 00 00 00 00 00 02 00 00 00 04 00 00 00 06 00 00 00 08 00 00 00 0a 00 00 00 0c 00 00 00 0c 00 00 00 0c 00 00 00 0c 00 00 00 0c 00 00 00 0c 00 00 03 00 00 00 04 00 00 00 05 00 00 00 06 00 00 00 07 00 00 00 08 00 00 00 09 00 00 00 09 00 00 00 09 00 00 00 09 00 00 00 09 00 00 00 09 00 00 00];
		};
		iq_rgbir {
			size = [2c 00 00 00];
			data = [01 00 00 00 00 00 00 00 cc 00 00 00 cc 00 00 00 e6 00 00 00 00 01 00 00 cc 00 00 00 cc 00 00 00 e6 00 00 00 dc 00 00 00 f0 00 00 00];
		};
		iq_rgbir_enh {
			size = [28 01 00 00];
			data = [01 00 00 00 00 00 00 00 32 00 00 00 10 00 00 00 10 00 00 00 10 00 00 00 10 00 00 00 10 00 00 00 10 00 00 00 10 00 00 00 10 00 00 00 10 00 00 00 10 00 00 00 10 00 00 00 10 00 00 00 10 00 00 00 10 00 00 00 10 00 00 00 10 00 00 00 ff ff 00 00 50 00 00 00 20 00 00 00 20 00 00 00 20 00 00 00 20 00 00 00 20 00 00 00 20 00 00 00 20 00 00 00 20 00 00 00 20 00 00 00 20 00 00 00 20 00 00 00 20 00 00 00 20 00 00 00 20 00 00 00 20 00 00 00 20 00 00 00 ff ff 00 00 98 00 00 00 50 00 00 00 50 00 00 00 50 00 00 00 50 00 00 00 50 00 00 00 50 00 00 00 50 00 00 00 50 00 00 00 50 00 00 00 50 00 00 00 50 00 00 00 50 00 00 00 50 00 00 00 50 00 00 00 50 00 00 00 50 00 00 00 ff ff 00 00 ff 00 00 00 a0 00 00 00 a0 00 00 00 a0 00 00 00 a0 00 00 00 a0 00 00 00 a0 00 00 00 a0 00 00 00 a0 00 00 00 a0 00 00 00 a0 00 00 00 a0 00 00 00 a0 00 00 00 a0 00 00 00 a0 00 00 00 a0 00 00 00 a0 00 00 00 ff ff 00 00];
		};
		iq_post_sharpen_2 {
			size = [4c 02 00 00];
			data = [01 00 00 00 00 00 00 00 19 23 23 23 23 23 23 23 23 23 23 23 23 23 23 23 23 23 02 ff 96 00 fa 00 20 ff 80 80 ff 00 40 20 80 80 19 23 23 23 23 23 23 23 23 23 23 23 23 23 23 23 23 23 02 ff 96 00 fa 00 20 ff 80 80 ff 00 40 20 80 80 19 23 23 23 23 23 23 23 23 23 23 23 23 23 23 23 23 23 02 ff 96 00 fa 00 20 ff 80 80 ff 00 40 20 80 80 19 23 23 23 23 23 23 23 23 23 23 23 23 23 23 23 23 23 02 ff 96 00 fa 00 20 ff 80 80 ff 00 40 20 80 80 19 23 23 23 23 23 23 23 23 23 23 23 23 23 23 23 23 23 02 ff 96 00 fa 00 20 ff 80 80 ff 00 40 20 80 80 19 23 23 23 23 23 23 23 23 23 23 23 23 23 23 23 23 23 02 ff 96 00 fa 00 20 ff 80 80 ff 00 40 20 80 80 19 23 23 23 23 23 23 23 23 23 23 23 23 23 23 23 23 23 02 ff 96 00 fa 00 20 ff 80 80 ff 00 40 20 80 80 19 23 23 23 23 23 23 23 23 23 23 23 23 23 23 23 23 23 02 ff 96 00 fa 00 20 ff 80 80 ff 00 40 20 80 80 19 23 23 23 23 23 23 23 23 23 23 23 23 23 23 23 23 23 02 ff 96 00 fa 00 20 ff 80 80 ff 00 40 20 80 80 19 23 23 23 23 23 23 23 23 23 23 23 23 23 23 23 23 23 02 ff 96 00 fa 00 20 ff 80 80 ff 00 40 20 80 80 19 23 23 23 23 23 23 23 23 23 23 23 23 23 23 23 23 23 02 ff 96 00 fa 00 20 ff 80 80 ff 00 40 20 80 80 19 23 23 23 23 23 23 23 23 23 23 23 23 23 23 23 23 23 02 ff 96 00 fa 00 20 ff 80 80 ff 00 40 20 80 80 19 23 23 23 23 23 23 23 23 23 23 23 23 23 23 23 23 23 02 ff 96 00 fa 00 20 ff 80 80 ff 00 40 20 80 80 19 23 23 23 23 23 23 23 23 23 23 23 23 23 23 23 23 23 02 ff 96 00 fa 00 20 ff 80 80 ff 00 40 20 80 80 19 23 23 23 23 23 23 23 23 23 23 23 23 23 23 23 23 23 02 ff 96 00 fa 00 20 ff 80 80 ff 00 40 20 80 80 19 23 23 23 23 23 23 23 23 23 23 23 23 23 23 23 23 23 02 ff 96 00 fa 00 20 ff 80 80 ff 00 40 20 80 80 19 23 23 23 23 23 23 23 23 23 23 23 23 23 23 23 23 23 02 ff 96 00 fa 00 20 ff 80 80 ff 00 40 20 80 80 00 00];
		};
		iq_ycurve {
			size = [08 02 00 00];
			data = [00 00 00 00 00 00 00 00 02 00 00 00 04 00 00 00 06 00 00 00 08 00 00 00 0a 00 00 00 0c 00 00 00 0e 00 00 00 10 00 00 00 12 00 00 00 14 00 00 00 16 00 00 00 18 00 00 00 1a 00 00 00 1c 00 00 00 1e 00 00 00 20 00 00 00 22 00 00 00 24 00 00 00 26 00 00 00 28 00 00 00 2a 00 00 00 2c 00 00 00 2e 00 00 00 30 00 00 00 32 00 00 00 34 00 00 00 36 00 00 00 38 00 00 00 3a 00 00 00 3c 00 00 00 3e 00 00 00 40 00 00 00 42 00 00 00 44 00 00 00 46 00 00 00 48 00 00 00 4a 00 00 00 4c 00 00 00 4e 00 00 00 50 00 00 00 52 00 00 00 54 00 00 00 56 00 00 00 58 00 00 00 5a 00 00 00 5c 00 00 00 5e 00 00 00 60 00 00 00 62 00 00 00 64 00 00 00 66 00 00 00 68 00 00 00 6a 00 00 00 6c 00 00 00 6e 00 00 00 70 00 00 00 72 00 00 00 74 00 00 00 76 00 00 00 78 00 00 00 7a 00 00 00 7c 00 00 00 7e 00 00 00 80 00 00 00 82 00 00 00 84 00 00 00 86 00 00 00 88 00 00 00 8a 00 00 00 8c 00 00 00 8e 00 00 00 90 00 00 00 92 00 00 00 94 00 00 00 96 00 00 00 98 00 00 00 9a 00 00 00 9c 00 00 00 9e 00 00 00 a0 00 00 00 a2 00 00 00 a4 00 00 00 a6 00 00 00 a8 00 00 00 aa 00 00 00 ac 00 00 00 ae 00 00 00 b0 00 00 00 b2 00 00 00 b4 00 00 00 b6 00 00 00 b8 00 00 00 ba 00 00 00 bc 00 00 00 be 00 00 00 c0 00 00 00 c2 00 00 00 c4 00 00 00 c6 00 00 00 c8 00 00 00 ca 00 00 00 cc 00 00 00 ce 00 00 00 d0 00 00 00 d2 00 00 00 d4 00 00 00 d6 00 00 00 d8 00 00 00 da 00 00 00 dc 00 00 00 de 00 00 00 e0 00 00 00 e2 00 00 00 e4 00 00 00 e6 00 00 00 e8 00 00 00 ea 00 00 00 ec 00 00 00 ee 00 00 00 f0 00 00 00 f2 00 00 00 f4 00 00 00 f6 00 00 00 f8 00 00 00 fa 00 00 00 fc 00 00 00 fe 00 00 00 ff 00 00 00];
		};
		iq_cst {
			size = [2c 00 00 00];
			data = [00 00 00 00 4d 00 96 00 1d 00 d5 ff ab ff 80 00 80 00 95 ff eb ff 00 00 80 80 02 02 02 02 02 02 02 02 02 02 02 02 02 02 02 02 02 00];
		};
	};
};
